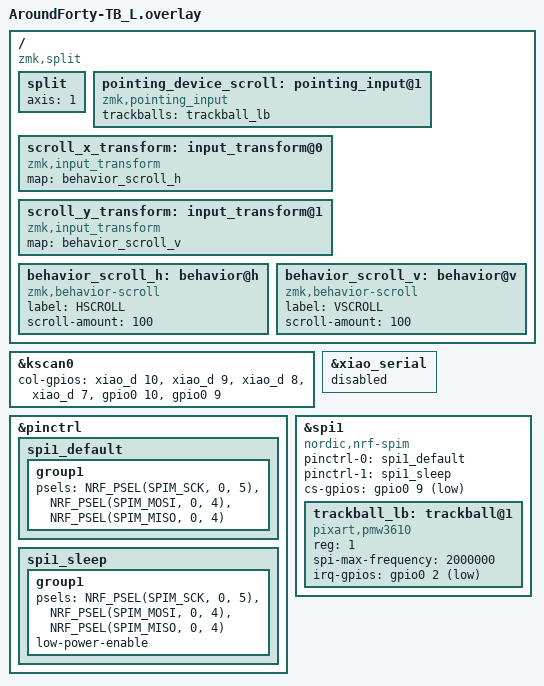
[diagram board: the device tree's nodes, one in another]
#include "AroundForty-TB.dtsi"

/* --- キー行列定義（既存のまま） */
&kscan0 {
    col-gpios = 
        <&xiao_d 10 GPIO_ACTIVE_HIGH>,
        <&xiao_d 9  GPIO_ACTIVE_HIGH>,
        <&xiao_d 8  GPIO_ACTIVE_HIGH>,
        <&xiao_d 7  GPIO_ACTIVE_HIGH>,
        <&gpio0 10 GPIO_ACTIVE_HIGH>,
        <&gpio0  9 GPIO_ACTIVE_HIGH>;
};

/* --- 1) SPI1 用 pinctrl 定義 --- */
&pinctrl {
    spi1_default: spi1_default {
        group1 {
            psels = 
                <NRF_PSEL(SPIM_SCK,  0, 5)>,   /* SCLK → P0.05 */
                <NRF_PSEL(SPIM_MOSI, 0, 4)>,   /* SDIO → P0.04 */
                <NRF_PSEL(SPIM_MISO, 0, 4)>;   /* SDIO → P0.04 */
        };
    };
    spi1_sleep: spi1_sleep {
        group1 {
            psels = 
                <NRF_PSEL(SPIM_SCK,  0, 5)>,
                <NRF_PSEL(SPIM_MOSI, 0, 4)>,
                <NRF_PSEL(SPIM_MISO, 0, 4)>;
            low-power-enable;
        };
    };
};

/* --- 2) シリアル無効化（任意） --- */
&xiao_serial {
    status = "disabled";
};

/* --- 3) SPI1 本体設定 --- */
&spi1 {
    status        = "okay";
    compatible    = "nordic,nrf-spim";
    pinctrl-0     = <&spi1_default>;
    pinctrl-1     = <&spi1_sleep>;
    pinctrl-names = "default", "sleep";

    /* チップセレクトだけ上書き */
    cs-gpios      = <&gpio0 9 GPIO_ACTIVE_LOW>;   /* NCS → P0.09 */

    /* 左手トラックボール (PMW3610) */
    trackball_lb: trackball@1 {
        compatible        = "pixart,pmw3610";
        reg               = <1>;
        spi-max-frequency = <2000000>;
        irq-gpios         = <&gpio0 2 (GPIO_ACTIVE_LOW | GPIO_PULL_UP)>; /* MOTION → P0.02 */
        status            = "okay";
    };
};

/* --- 4) Split クライアント化 & スクロール設定 --- */
 / {
    compatible = "zmk,split";
    split {
        status = "okay";
        axis   = <1>;
    };

    /* 左手側トラックボールをスクロール入力として扱う */
    pointing_device_scroll: pointing_input@1 {
        compatible  = "zmk,pointing_input";
        trackballs  = <&trackball_lb>;
        status      = "okay";
    };

    /* 水平／垂直スクロール変換 */
    scroll_x_transform: input_transform@0 {
        compatible = "zmk,input_transform";
        map        = <&behavior_scroll_h>;
    };
    scroll_y_transform: input_transform@1 {
        compatible = "zmk,input_transform";
        map        = <&behavior_scroll_v>;
    };

    /* スクロールビヘイビア */
    behavior_scroll_h: behavior@h {
        compatible    = "zmk,behavior-scroll";
        label         = "HSCROLL";
        scroll-amount = <100>;  /* お好みで調整 */
    };
    behavior_scroll_v: behavior@v {
        compatible    = "zmk,behavior-scroll";
        label         = "VSCROLL";
        scroll-amount = <100>;  /* お好みで調整 */
    };
};
